# HT32F1653_54 register map
File version: 1.1
CPU: CM3 r2p0, little endian, no MPU, no FPU, 4 interrupt priority bits
Registers are 32-bit, read-write, reset 0x0 unless marked. A register's access mark holds for its fields unless they carry their own. Offsets are from the block's base; [hi:lo] are bit positions; {n}, {i} and the like mark numbered series.

## RSTCU
Base 0x40088100
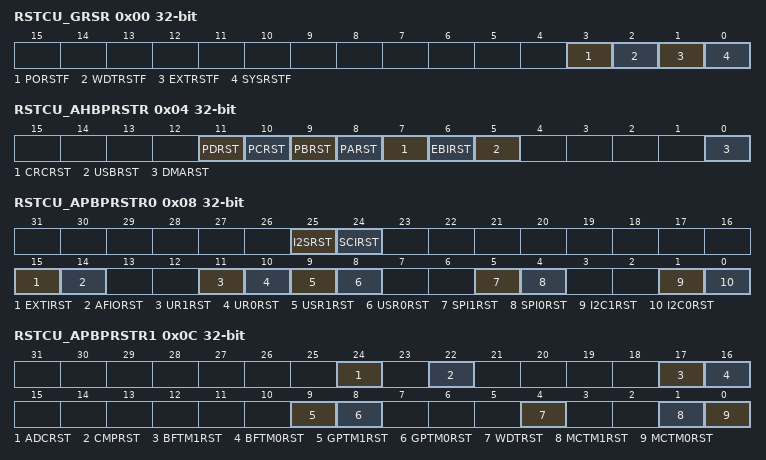
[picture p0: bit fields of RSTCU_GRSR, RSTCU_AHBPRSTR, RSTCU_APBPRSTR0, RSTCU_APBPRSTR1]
0x00 RSTCU_GRSR
  [3] PORSTF, [2] WDTRSTF, [1] EXTRSTF, [0] SYSRSTF
0x04 RSTCU_AHBPRSTR
  [11] PDRST, [10] PCRST, [9] PBRST, [8] PARST, [7] CRCRST, [6] EBIRST, [5] USBRST, [0] DMARST
0x08 RSTCU_APBPRSTR0
  [25] I2SRST, [24] SCIRST, [15] EXTIRST, [14] AFIORST, [11] UR1RST, [10] UR0RST, [9] USR1RST, [8] USR0RST, [5] SPI1RST, [4] SPI0RST, [1] I2C1RST, [0] I2C0RST
0x0C RSTCU_APBPRSTR1
  [24] ADCRST, [22] CMPRST, [17] BFTM1RST, [16] BFTM0RST, [9] GPTM1RST, [8] GPTM0RST, [4] WDTRST, [1] MCTM1RST, [0] MCTM0RST

## GPIOA
Base 0x400B0000
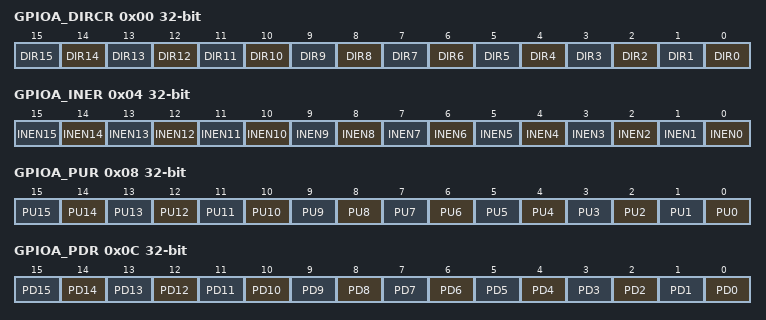
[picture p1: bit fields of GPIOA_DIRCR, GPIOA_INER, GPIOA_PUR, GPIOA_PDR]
0x00 GPIOA_DIRCR
  [n] DIR{n} (n=0..15)
0x04 GPIOA_INER
  [n] INEN{n} (n=0..15)
0x08 GPIOA_PUR
  [n] PU{n} (n=0..15)
0x0C GPIOA_PDR
  [n] PD{n} (n=0..15)
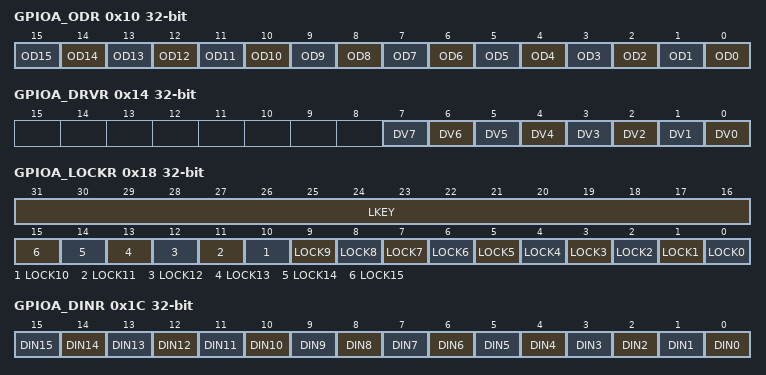
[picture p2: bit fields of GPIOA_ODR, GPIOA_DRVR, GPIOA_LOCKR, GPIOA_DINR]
0x10 GPIOA_ODR
  [n] OD{n} (n=0..15)
0x14 GPIOA_DRVR
  [n] DV{n} (n=0..7)
0x18 GPIOA_LOCKR
  [31:16] LKEY, [n] LOCK{n} (n=0..15)
0x1C GPIOA_DINR
  [n] DIN{n} (n=0..15)
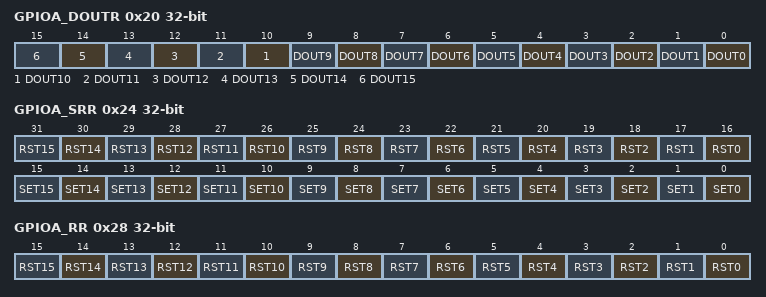
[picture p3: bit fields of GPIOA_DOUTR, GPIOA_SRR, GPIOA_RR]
0x20 GPIOA_DOUTR
  [n] DOUT{n} (n=0..15)
0x24 GPIOA_SRR
  [n+16] RST{n} (n=0..15), [n] SET{n} (n=0..15)
0x28 GPIOA_RR
  [n] RST{n} (n=0..15)

## GPIOB
Base 0x400B2000
Registers as GPIOA (with GPIOA read as GPIOB); these are added or differ:
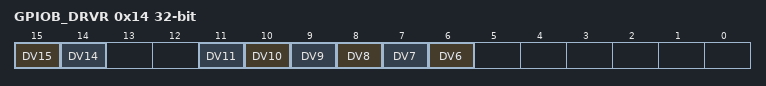
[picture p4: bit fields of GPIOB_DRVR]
0x14 GPIOB_DRVR
  [15] DV15, [14] DV14, [n] DV{n} (n=6..11)

## GPIOC
Base 0x400B4000
Registers as GPIOA (with GPIOA read as GPIOC); these are added or differ:
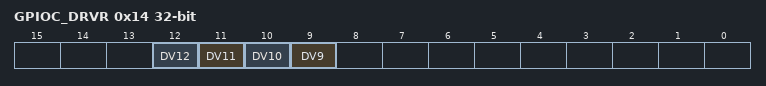
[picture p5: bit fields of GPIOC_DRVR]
0x14 GPIOC_DRVR
  [n] DV{n} (n=9..12)

## GPIOD
Base 0x400B6000
Registers as GPIOA (with GPIOA read as GPIOD); these are added or differ:
0x14 GPIOD_DRVR
  [6] DV6

## AFIO
Base 0x40022000
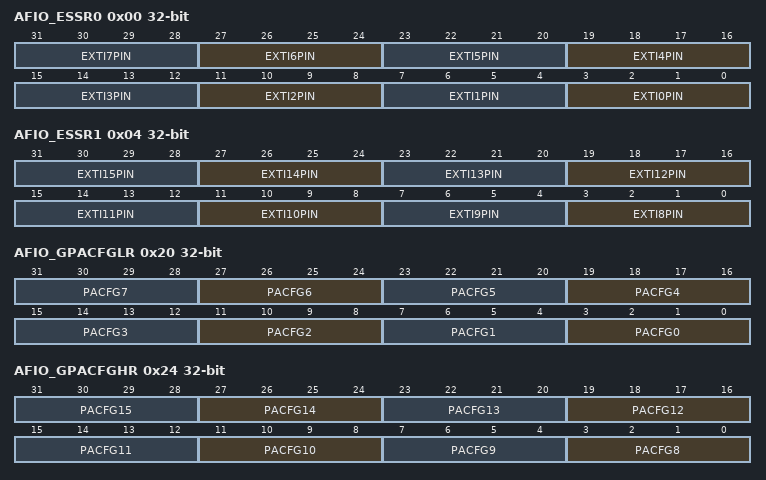
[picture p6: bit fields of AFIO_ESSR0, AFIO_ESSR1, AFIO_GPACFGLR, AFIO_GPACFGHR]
0x00 AFIO_ESSR0
  [4n+3:4n] EXTI{n}PIN (n=0..7)
0x04 AFIO_ESSR1
  [4n-29:4n-32] EXTI{n}PIN (n=8..15)
0x20 AFIO_GPACFGLR
  [4n+3:4n] PACFG{n} (n=0..7)
0x24 AFIO_GPACFGHR
  [4n-29:4n-32] PACFG{n} (n=8..15)
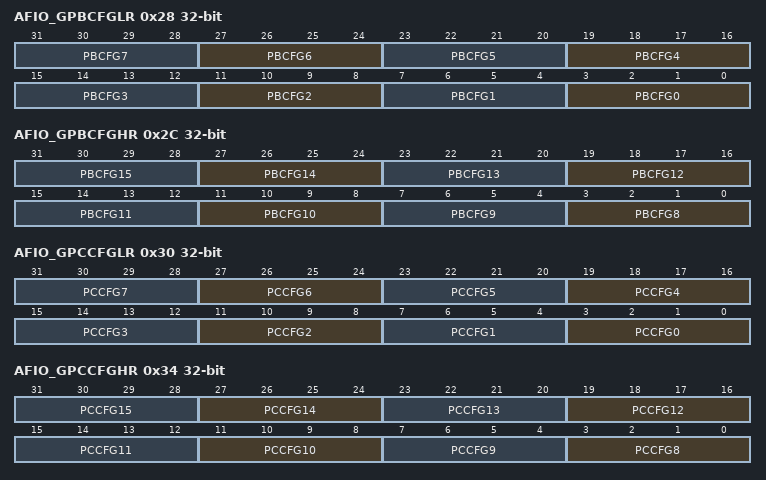
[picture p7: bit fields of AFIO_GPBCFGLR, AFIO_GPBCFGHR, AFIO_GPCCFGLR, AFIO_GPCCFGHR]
0x28 AFIO_GPBCFGLR
  [4n+3:4n] PBCFG{n} (n=0..7)
0x2C AFIO_GPBCFGHR
  [4n-29:4n-32] PBCFG{n} (n=8..15)
0x30 AFIO_GPCCFGLR
  [4n+3:4n] PCCFG{n} (n=0..7)
0x34 AFIO_GPCCFGHR
  [4n-29:4n-32] PCCFG{n} (n=8..15)
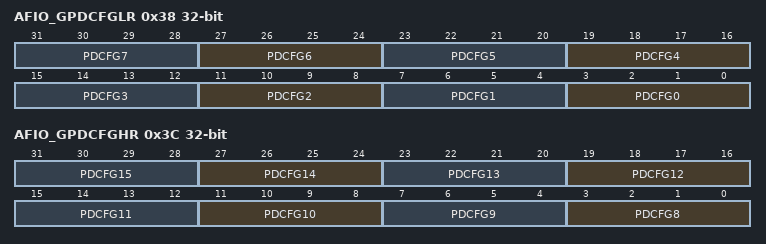
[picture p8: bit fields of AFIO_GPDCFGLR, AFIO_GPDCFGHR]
0x38 AFIO_GPDCFGLR
  [4n+3:4n] PDCFG{n} (n=0..7)
0x3C AFIO_GPDCFGHR
  [4n-29:4n-32] PDCFG{n} (n=8..15)

## EXTI
Base 0x40024000
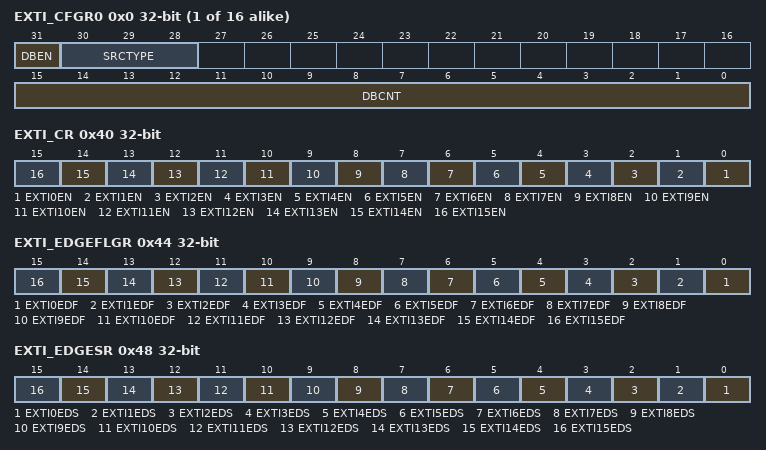
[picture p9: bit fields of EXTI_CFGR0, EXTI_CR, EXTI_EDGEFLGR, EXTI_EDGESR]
{0x0+4i} EXTI_CFGR{i} (i=0..15)
  [31] DBEN, [30:28] SRCTYPE, [15:0] DBCNT
0x40 EXTI_CR
  [n] EXTI{n}EN (n=0..15)
0x44 EXTI_EDGEFLGR
  [n] EXTI{n}EDF (n=0..15)
0x48 EXTI_EDGESR
  [n] EXTI{n}EDS (n=0..15)
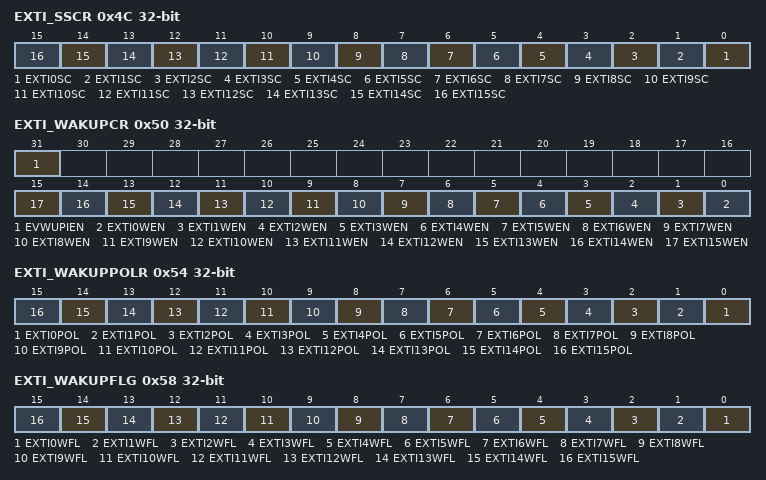
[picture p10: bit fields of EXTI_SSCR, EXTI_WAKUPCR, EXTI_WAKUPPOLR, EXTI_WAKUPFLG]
0x4C EXTI_SSCR
  [n] EXTI{n}SC (n=0..15)
0x50 EXTI_WAKUPCR
  [31] EVWUPIEN, [n] EXTI{n}WEN (n=0..15)
0x54 EXTI_WAKUPPOLR
  [n] EXTI{n}POL (n=0..15)
0x58 EXTI_WAKUPFLG
  [n] EXTI{n}WFL (n=0..15)

## ADC
Base 0x40010000
0x04 ADC_RST
  [0] ADRST
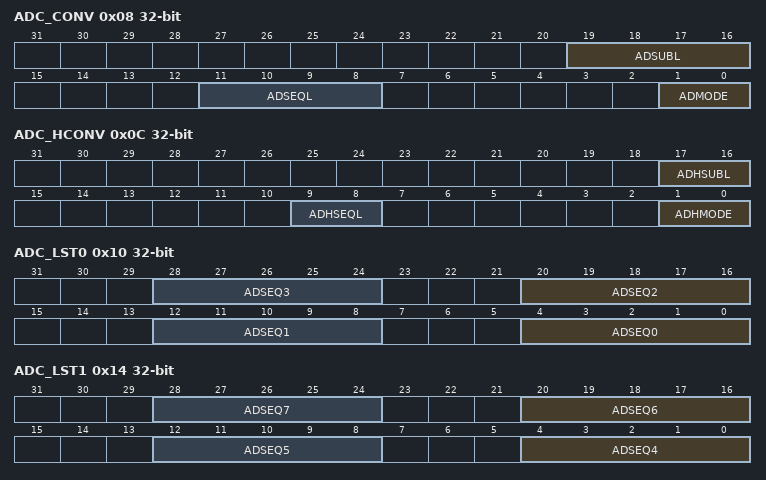
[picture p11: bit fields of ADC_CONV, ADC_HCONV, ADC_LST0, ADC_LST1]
0x08 ADC_CONV
  [19:16] ADSUBL, [11:8] ADSEQL, [1:0] ADMODE
0x0C ADC_HCONV
  [17:16] ADHSUBL, [9:8] ADHSEQL, [1:0] ADHMODE
0x10 ADC_LST0
  [8n+4:8n] ADSEQ{n} (n=0..3)
0x14 ADC_LST1
  [8n-28:8n-32] ADSEQ{n} (n=4..7)
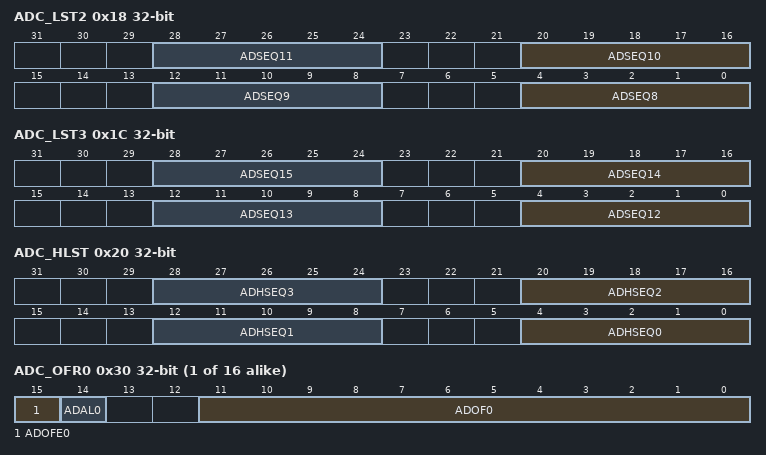
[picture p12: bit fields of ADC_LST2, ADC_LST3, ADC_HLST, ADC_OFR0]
0x18 ADC_LST2
  [8n-60:8n-64] ADSEQ{n} (n=8..11)
0x1C ADC_LST3
  [8n-92:8n-96] ADSEQ{n} (n=12..15)
0x20 ADC_HLST
  [8n+4:8n] ADHSEQ{n} (n=0..3)
{0x30+4i} ADC_OFR{i} (i=0..15)
  [15] ADOFE{i}, [14] ADAL{i}, [11:0] ADOF{i}
{0x70+4i} ADC_STR{i} (i=0..15)
  [7:0] ADST{i}
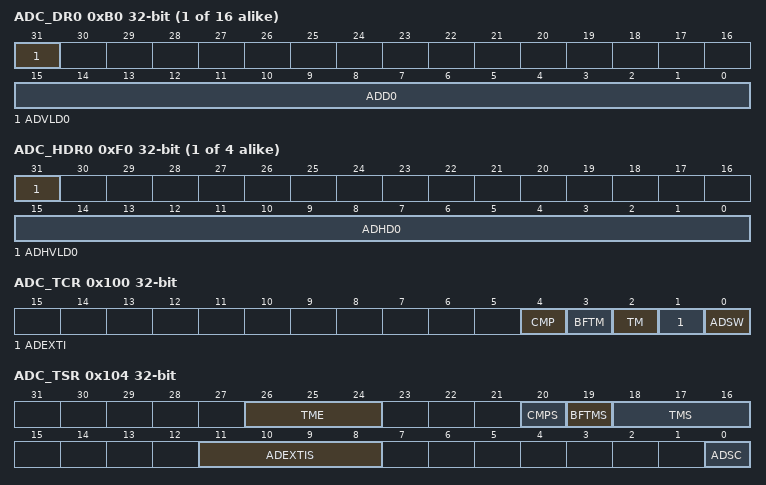
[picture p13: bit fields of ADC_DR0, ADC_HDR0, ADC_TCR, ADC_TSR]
{0xB0+4i} ADC_DR{i} (i=0..15)
  [31] ADVLD{i}, [15:0] ADD{i}
{0xF0+4i} ADC_HDR{i} (i=0..3)
  [31] ADHVLD{i}, [15:0] ADHD{i}
0x100 ADC_TCR
  [4] CMP, [3] BFTM, [2] TM, [1] ADEXTI, [0] ADSW
0x104 ADC_TSR
  [26:24] TME, [20] CMPS, [19] BFTMS, [18:16] TMS, [11:8] ADEXTIS, [0] ADSC
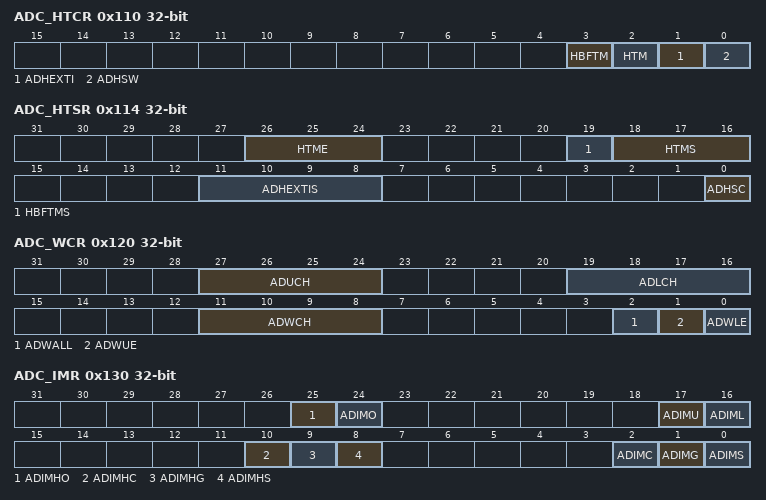
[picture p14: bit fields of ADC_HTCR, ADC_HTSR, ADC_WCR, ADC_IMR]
0x110 ADC_HTCR
  [3] HBFTM, [2] HTM, [1] ADHEXTI, [0] ADHSW
0x114 ADC_HTSR
  [26:24] HTME, [19] HBFTMS, [18:16] HTMS, [11:8] ADHEXTIS, [0] ADHSC
0x120 ADC_WCR
  [27:24] ADUCH, [19:16] ADLCH, [11:8] ADWCH, [2] ADWALL, [1] ADWUE, [0] ADWLE
0x124 ADC_LTR
  [11:0] ADLT
0x128 ADC_UTR
  [11:0] ADUT
0x130 ADC_IMR
  [25] ADIMHO
  [24] ADIMO
  [17] ADIMU
  [16] ADIML
  [10] ADIMHC — ADIMC
  [9] ADIMHG
  [8] ADIMHS
  [2] ADIMC
  [1] ADIMG
  [0] ADIMS
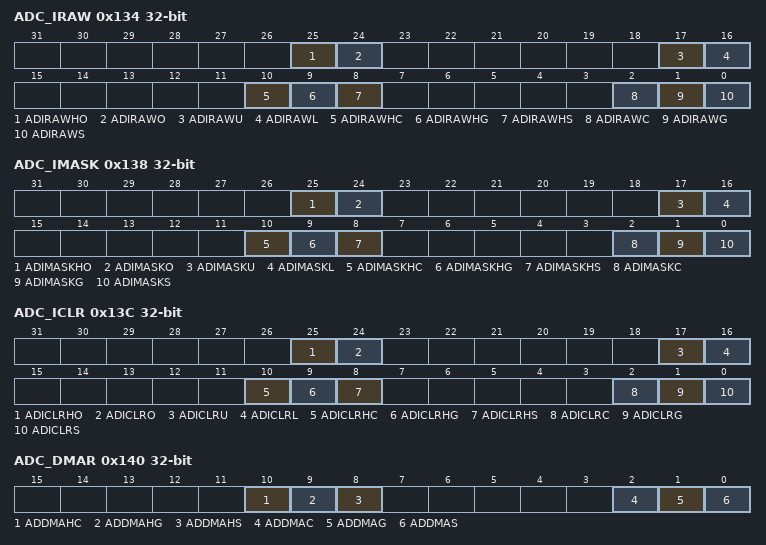
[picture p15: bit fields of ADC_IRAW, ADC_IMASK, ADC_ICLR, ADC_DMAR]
0x134 ADC_IRAW
  [25] ADIRAWHO, [24] ADIRAWO, [17] ADIRAWU, [16] ADIRAWL, [10] ADIRAWHC, [9] ADIRAWHG, [8] ADIRAWHS, [2] ADIRAWC, [1] ADIRAWG, [0] ADIRAWS
0x138 ADC_IMASK
  [25] ADIMASKHO, [24] ADIMASKO, [17] ADIMASKU, [16] ADIMASKL, [10] ADIMASKHC, [9] ADIMASKHG, [8] ADIMASKHS, [2] ADIMASKC, [1] ADIMASKG, [0] ADIMASKS
0x13C ADC_ICLR
  [25] ADICLRHO, [24] ADICLRO, [17] ADICLRU, [16] ADICLRL, [10] ADICLRHC, [9] ADICLRHG, [8] ADICLRHS, [2] ADICLRC, [1] ADICLRG, [0] ADICLRS
0x140 ADC_DMAR
  [10] ADDMAHC, [9] ADDMAHG, [8] ADDMAHS, [2] ADDMAC, [1] ADDMAG, [0] ADDMAS

## Notices in the file
Copyright (C) 2010 ARM Limited. All rights reserved.
ARM Limited (ARM) is supplying this SVD description for use with Cortex-M3
processor based microcontrollers.  This file and or content can be freely
distributed within development tools that are supporting such ARM based
processors.
THIS SOFTWARE IS PROVIDED "AS IS".  NO WARRANTIES, WHETHER EXPRESS, IMPLIED
OR STATUTORY, INCLUDING, BUT NOT LIMITED TO, IMPLIED WARRANTIES OF
MERCHANTABILITY AND FITNESS FOR A PARTICULAR PURPOSE APPLY TO THIS SOFTWARE.
ARM SHALL NOT, IN ANY CIRCUMSTANCES, BE LIABLE FOR SPECIAL, INCIDENTAL, OR
CONSEQUENTIAL DAMAGES, FOR ANY REASON WHATSOEVER.
